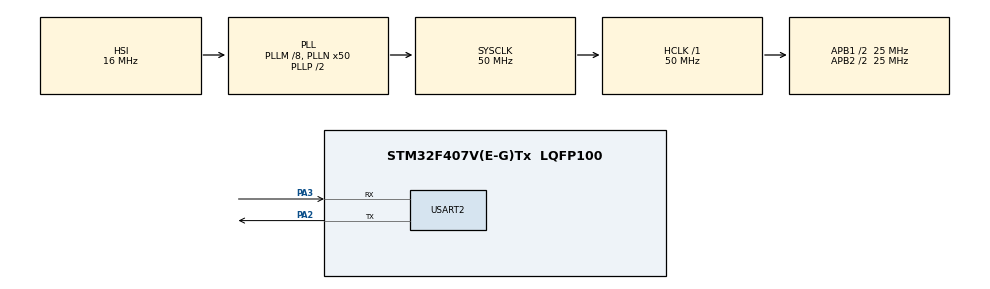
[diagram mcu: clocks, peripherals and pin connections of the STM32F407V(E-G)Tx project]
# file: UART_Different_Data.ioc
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Mcu.Family=STM32F4
Mcu.Name=STM32F407V(E-G)Tx
Mcu.Package=LQFP100
NVIC.PriorityGroup=NVIC_PRIORITYGROUP_0
PA13.Mode=Serial_Wire
PA13.Signal=SYS_JTMS-SWDIO
PA14.Mode=Serial_Wire
PA14.Signal=SYS_JTCK-SWCLK
PA2.Mode=Asynchronous
PA2.Signal=USART2_TX
PA3.Mode=Asynchronous
PA3.Signal=USART2_RX
PH0-OSC_IN.Mode=HSE-External-Oscillator
PH0-OSC_IN.Signal=RCC_OSC_IN
PH1-OSC_OUT.Mode=HSE-External-Oscillator
PH1-OSC_OUT.Signal=RCC_OSC_OUT
ProjectManager.HeapSize=0x200
ProjectManager.StackSize=0x400
ProjectManager.TargetToolchain=STM32CubeIDE
RCC.48MHZClocksFreq_Value=14285714.285714285
RCC.AHBFreq_Value=50000000
RCC.APB1CLKDivider=RCC_HCLK_DIV2
RCC.APB1Freq_Value=25000000
RCC.APB1TimFreq_Value=50000000
RCC.APB2CLKDivider=RCC_HCLK_DIV2
RCC.APB2Freq_Value=25000000
RCC.APB2TimFreq_Value=50000000
RCC.CortexFreq_Value=50000000
RCC.HCLKFreq_Value=50000000
RCC.HSE_VALUE=8000000
RCC.HSI_VALUE=16000000
RCC.PLLM=8
RCC.PLLN=50
RCC.PLLQ=7
RCC.SYSCLKFreq_VALUE=50000000
RCC.SYSCLKSource=RCC_SYSCLKSOURCE_PLLCLK
RCC.VCOOutputFreq_Value=100000000
USART2.VirtualMode=VM_ASYNC
board=STM32F407G-DISC1

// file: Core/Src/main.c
/* USER CODE BEGIN Header */
/**
  ******************************************************************************
  * @file           : main.c
  * @brief          : Main program body
  ******************************************************************************
  * @attention
  *
  * Copyright (c) 2026 STMicroelectronics.
  * All rights reserved.
  *
  * This software is licensed under terms that can be found in the LICENSE file
  * in the root directory of this software component.
  * If no LICENSE file comes with this software, it is provided AS-IS.
  *
  ******************************************************************************
  */
/* USER CODE END Header */
#include "main.h"

/* USER CODE BEGIN Includes */
#include "string.h"
#include "stdio.h"
/* USER CODE END Includes */

UART_HandleTypeDef huart2;

/* USER CODE BEGIN PV */

char single_char = 'A';
char multiple_char[] = {'C','R', 'I', 'C', 'K', 'E', 'T', 'E', 'R'};
char carriage_return = '\r';
char line_feed = '\n';
char carriage_linefeed[3] = {"\r\n"};
char init_msg[] = "UART Initialized\r\n";
char string_msg[20] = "Hello via UART\r\n";
char number8 = 0  + '0';
uint8_t number8_1 = 1 + '0';

uint16_t number16 = 1000;
char buffer8[10];

uint32_t number32 = 45454545;

uint8_t hex_msg = 0xAB;
uint32_t hex_msg32 = 0xABCDEF87;

/* USER CODE END PV */

void SystemClock_Config(void);
static void MX_GPIO_Init(void);
static void MX_USART2_UART_Init(void);

int main(void)
{

  /* MCU Configuration--------------------------------------------------------*/

  /* Reset of all peripherals, Initializes the Flash interface and the Systick. */
  HAL_Init();

  /* Configure the system clock */
  SystemClock_Config();

  /* Initialize all configured peripherals */
  MX_GPIO_Init();
  MX_USART2_UART_Init();

  /* Infinite loop */
  /* USER CODE BEGIN WHILE */

  HAL_UART_Transmit(&huart2, (uint8_t *)init_msg, strlen(init_msg), HAL_MAX_DELAY);

  //Transmit single character
  HAL_UART_Transmit(&huart2, (uint8_t *)&single_char, 1, HAL_MAX_DELAY);

  //Transmit carriage return character
  HAL_UART_Transmit(&huart2, (uint8_t *)&carriage_return, 1 , HAL_MAX_DELAY);

  //Transmit carriage return character
  HAL_UART_Transmit(&huart2, (uint8_t *)&line_feed, 1 , HAL_MAX_DELAY);

  //Transmit multiple character
  HAL_UART_Transmit(&huart2, (uint8_t *)multiple_char, 9 , HAL_MAX_DELAY);
  HAL_UART_Transmit(&huart2, (uint8_t *)carriage_linefeed, strlen(carriage_linefeed) , HAL_MAX_DELAY);

  //Transmit string
  HAL_UART_Transmit(&huart2, (uint8_t *)string_msg, strlen(string_msg) , HAL_MAX_DELAY);

  //Transmit single number
  HAL_UART_Transmit(&huart2, (uint8_t *)&number8, 1 , HAL_MAX_DELAY);
  HAL_UART_Transmit(&huart2, (uint8_t *)carriage_linefeed, strlen(carriage_linefeed) , HAL_MAX_DELAY);

  HAL_UART_Transmit(&huart2,&number8_1, 1 , HAL_MAX_DELAY);
  HAL_UART_Transmit(&huart2, (uint8_t *)carriage_linefeed, strlen(carriage_linefeed) , HAL_MAX_DELAY);

  //Transmit multiple numbers
  sprintf(buffer8,"%u",number16);
  HAL_UART_Transmit(&huart2, (uint8_t *)buffer8, strlen(buffer8) , HAL_MAX_DELAY);
  HAL_UART_Transmit(&huart2, (uint8_t *)carriage_linefeed, strlen(carriage_linefeed) , HAL_MAX_DELAY);

  //Transmit uint32 numbers
  sprintf(buffer8,"%lu",number32);
  HAL_UART_Transmit(&huart2, (uint8_t *)buffer8, strlen(buffer8) , HAL_MAX_DELAY);
  HAL_UART_Transmit(&huart2, (uint8_t *)carriage_linefeed, strlen(carriage_linefeed) , HAL_MAX_DELAY);

  //Transmit hex numbers
  sprintf(buffer8,"0x%02X",hex_msg);
  HAL_UART_Transmit(&huart2, (uint8_t *)buffer8, strlen(buffer8) , HAL_MAX_DELAY);
  HAL_UART_Transmit(&huart2, (uint8_t *)carriage_linefeed, strlen(carriage_linefeed) , HAL_MAX_DELAY);

  sprintf(buffer8,"0x%08lX",hex_msg32);
  HAL_UART_Transmit(&huart2, (uint8_t *)buffer8, strlen(buffer8) , HAL_MAX_DELAY);
  HAL_UART_Transmit(&huart2, (uint8_t *)carriage_linefeed, strlen(carriage_linefeed) , HAL_MAX_DELAY);

  while (1)
  {
    /* USER CODE END WHILE */

  }
}

void SystemClock_Config(void)
{
  RCC_OscInitTypeDef RCC_OscInitStruct = {0};
  RCC_ClkInitTypeDef RCC_ClkInitStruct = {0};

  /** Configure the main internal regulator output voltage
  */
  __HAL_RCC_PWR_CLK_ENABLE();
  __HAL_PWR_VOLTAGESCALING_CONFIG(PWR_REGULATOR_VOLTAGE_SCALE1);

  /** Initializes the RCC Oscillators according to the specified parameters
  * in the RCC_OscInitTypeDef structure.
  */
  RCC_OscInitStruct.OscillatorType = RCC_OSCILLATORTYPE_HSI;
  RCC_OscInitStruct.HSIState = RCC_HSI_ON;
  RCC_OscInitStruct.HSICalibrationValue = RCC_HSICALIBRATION_DEFAULT;
  RCC_OscInitStruct.PLL.PLLState = RCC_PLL_ON;
  RCC_OscInitStruct.PLL.PLLSource = RCC_PLLSOURCE_HSI;
  RCC_OscInitStruct.PLL.PLLM = 8;
  RCC_OscInitStruct.PLL.PLLN = 50;
  RCC_OscInitStruct.PLL.PLLP = RCC_PLLP_DIV2;
  RCC_OscInitStruct.PLL.PLLQ = 7;
  if (HAL_RCC_OscConfig(&RCC_OscInitStruct) != HAL_OK)
  {
    Error_Handler();
  }

  /** Initializes the CPU, AHB and APB buses clocks
  */
  RCC_ClkInitStruct.ClockType = RCC_CLOCKTYPE_HCLK|RCC_CLOCKTYPE_SYSCLK
                              |RCC_CLOCKTYPE_PCLK1|RCC_CLOCKTYPE_PCLK2;
  RCC_ClkInitStruct.SYSCLKSource = RCC_SYSCLKSOURCE_PLLCLK;
  RCC_ClkInitStruct.AHBCLKDivider = RCC_SYSCLK_DIV1;
  RCC_ClkInitStruct.APB1CLKDivider = RCC_HCLK_DIV2;
  RCC_ClkInitStruct.APB2CLKDivider = RCC_HCLK_DIV2;

  if (HAL_RCC_ClockConfig(&RCC_ClkInitStruct, FLASH_LATENCY_1) != HAL_OK)
  {
    Error_Handler();
  }
}

static void MX_USART2_UART_Init(void)
{

  huart2.Instance = USART2;
  huart2.Init.BaudRate = 115200;
  huart2.Init.WordLength = UART_WORDLENGTH_8B;
  huart2.Init.StopBits = UART_STOPBITS_1;
  huart2.Init.Parity = UART_PARITY_NONE;
  huart2.Init.Mode = UART_MODE_TX_RX;
  huart2.Init.HwFlowCtl = UART_HWCONTROL_NONE;
  huart2.Init.OverSampling = UART_OVERSAMPLING_16;
  if (HAL_UART_Init(&huart2) != HAL_OK)
  {
    Error_Handler();
  }

}

static void MX_GPIO_Init(void)
{

  /* GPIO Ports Clock Enable */
  __HAL_RCC_GPIOH_CLK_ENABLE();
  __HAL_RCC_GPIOA_CLK_ENABLE();

}

void Error_Handler(void)
{
  __disable_irq();
  while (1)
  {
  }
}
